# TMS320F280049 register map
Vendor: Texas Instruments; Series: C2000 F28004x; File version: 0.2.0-generated
Registers are 16-bit, read-write, reset 0x0 unless marked. A register's access mark holds for its fields unless they carry their own. Offsets are from the block's base; [hi:lo] are bit positions; {n}, {i} and the like mark numbered series.

## SYNCSOCREGS — SYNC SOC Registers
Base 0x0000F280
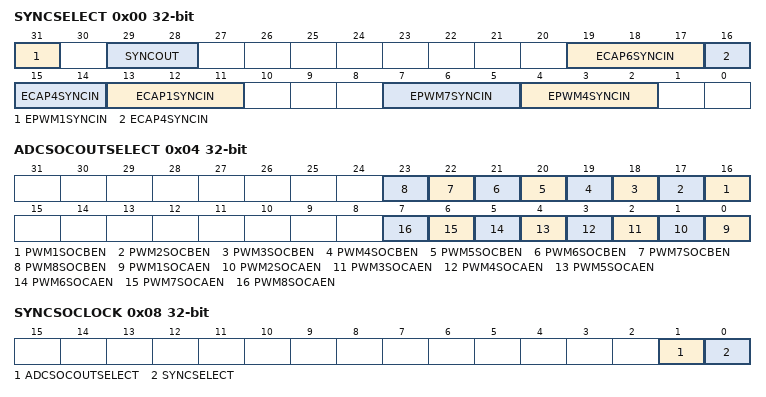
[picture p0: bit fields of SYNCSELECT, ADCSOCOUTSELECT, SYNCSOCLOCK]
0x00 SYNCSELECT 32-bit — Sync Input and Output Select Register
  [31] EPWM1SYNCIN — Selects Sync Input Source for EPWM1
  [29:28] SYNCOUT — Select Syncout Source
  [19:17] ECAP6SYNCIN — Selects Sync Input Source for ECAP6
  [16:14] ECAP4SYNCIN — Selects Sync Input Source for ECAP4
  [13:11] ECAP1SYNCIN — Selects Sync Input Source for ECAP1
  [7:5] EPWM7SYNCIN — Selects Sync Input Source for EPWM7
  [4:2] EPWM4SYNCIN — Selects Sync Input Source for EPWM4
0x04 ADCSOCOUTSELECT 32-bit — External ADCSOC Select Register
  [n+15] PWM{n}SOCBEN (n=1..8) — PWM{n}SOCBEN Enable for ADCSOCBOn
  [n-1] PWM{n}SOCAEN (n=1..8) — PWM{n}SOCAEN Enable for ADCSOCAOn
0x08 SYNCSOCLOCK 32-bit — SYNCSEL and EXTADCSOC Select Lock register
  [1] ADCSOCOUTSELECT — ADCSOCOUTSELECT Register Lock bit
  [0] SYNCSELECT — SYNCSEL Register Lock bit

## DMACLASRCSELREGS — DMA CLA SRC SEL Registers
Base 0x0000F300
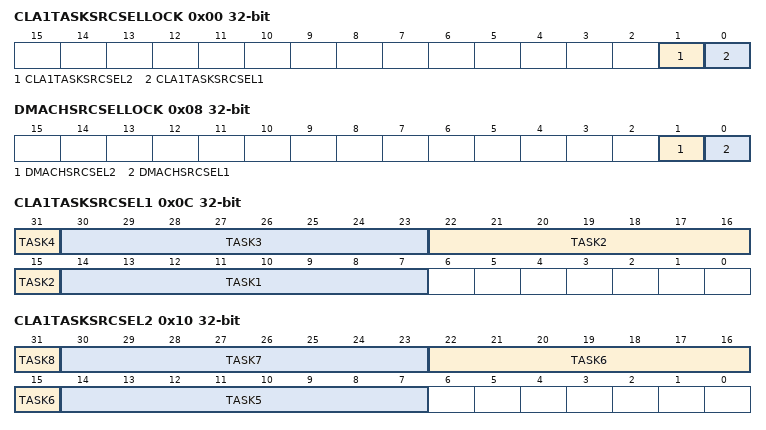
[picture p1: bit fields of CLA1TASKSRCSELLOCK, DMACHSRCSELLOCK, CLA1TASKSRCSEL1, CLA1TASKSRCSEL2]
0x00 CLA1TASKSRCSELLOCK 32-bit — CLA1 Task Trigger Source Select Lock Register
  [1] CLA1TASKSRCSEL2 — CLA1TASKSRCSEL2 Register Lock bit
  [0] CLA1TASKSRCSEL1 — CLA1TASKSRCSEL1 Register Lock bit
0x08 DMACHSRCSELLOCK 32-bit — DMA Channel Triger Source Select Lock Register
  [1] DMACHSRCSEL2 — DMACHSRCSEL2 Register Lock bit
  [0] DMACHSRCSEL1 — DMACHSRCSEL1 Register Lock bit
0x0C CLA1TASKSRCSEL1 32-bit — CLA1 Task Trigger Source Select Register-1
  [31] TASK4 — Selects the Trigger Source for TASK4 of CLA1
  [30:23] TASK3 — Selects the Trigger Source for TASK3 of CLA1
  [22:15] TASK2 — Selects the Trigger Source for TASK2 of CLA1
  [14:7] TASK1 — Selects the Trigger Source for TASK1 of CLA1
0x10 CLA1TASKSRCSEL2 32-bit — CLA1 Task Trigger Source Select Register-2
  [31] TASK8 — Selects the Trigger Source for TASK8 of CLA1
  [30:23] TASK7 — Selects the Trigger Source for TASK7 of CLA1
  [22:15] TASK6 — Selects the Trigger Source for TASK6 of CLA1
  [14:7] TASK5 — Selects the Trigger Source for TASK5 of CLA1
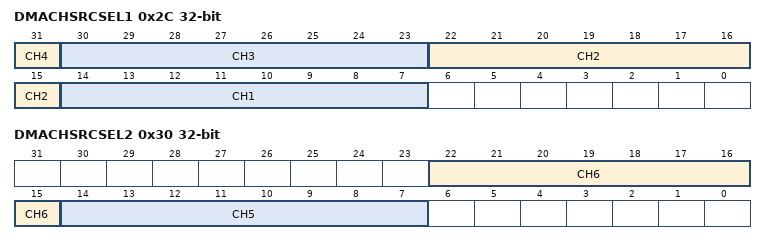
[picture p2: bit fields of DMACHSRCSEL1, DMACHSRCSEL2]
0x2C DMACHSRCSEL1 32-bit — DMA Channel Trigger Source Select Register-1
  [31] CH4 — Selects the Trigger and Sync Source CH4 of DMA
  [30:23] CH3 — Selects the Trigger and Sync Source CH3 of DMA
  [22:15] CH2 — Selects the Trigger and Sync Source CH2 of DMA
  [14:7] CH1 — Selects the Trigger and Sync Source CH1 of DMA
0x30 DMACHSRCSEL2 32-bit — DMA Channel Trigger Source Select Register-2
  [22:15] CH6 — Selects the Trigger and Sync Source CH6 of DMA
  [14:7] CH5 — Selects the Trigger and Sync Source CH5 of DMA

## GPIODATAREGS — GPIO DATA Registers
Base 0x0000FE00
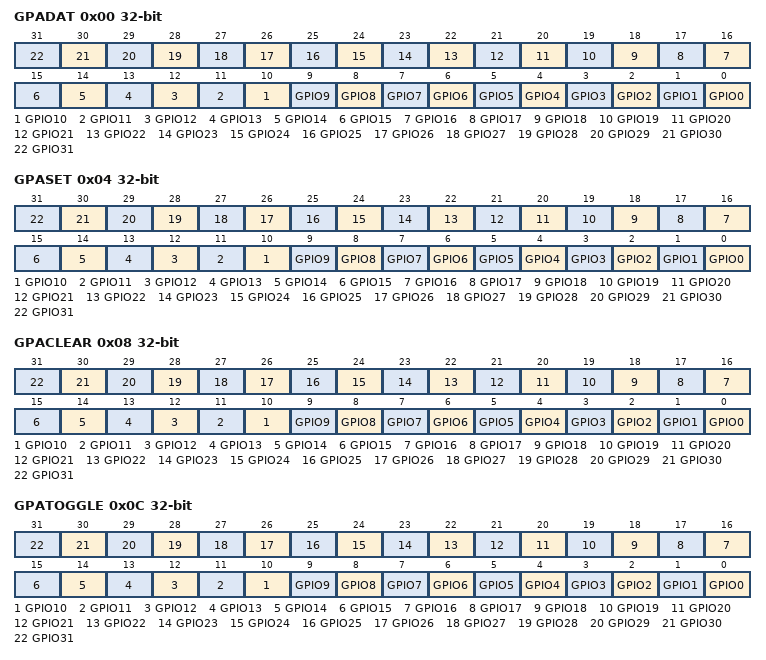
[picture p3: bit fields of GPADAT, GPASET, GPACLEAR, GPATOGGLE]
0x00 GPADAT 32-bit — GPIO A Data Register (GPIO0 to GPIO31)
  [n] GPIO{n} (n=0..31) — Data Register for this pin
0x04 GPASET 32-bit — GPIO A Output Set (GPIO0 to GPIO31)
  [n] GPIO{n} (n=0..31) — Output Set bit for this pin
0x08 GPACLEAR 32-bit — GPIO A Output Clear (GPIO0 to GPIO31)
  [n] GPIO{n} (n=0..31) — Output Clear bit for this pin
0x0C GPATOGGLE 32-bit — GPIO A Output Toggle (GPIO0 to GPIO31)
  [n] GPIO{n} (n=0..31) — Output Toggle bit for this pin
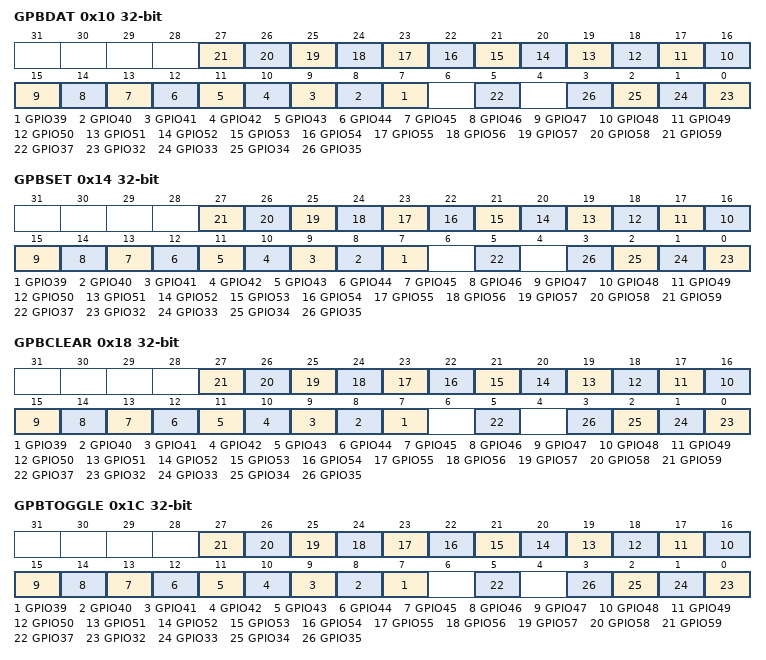
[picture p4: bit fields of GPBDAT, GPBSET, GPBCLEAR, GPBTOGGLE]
0x10 GPBDAT 32-bit — GPIO B Data Register (GPIO32 to GPIO64)
  [n-32] GPIO{n} (n=39..59) — Data Register for this pin
  [5] GPIO37 — Data Register for this pin
  [n-32] GPIO{n} (n=32..35) — Data Register for this pin
0x14 GPBSET 32-bit — GPIO B Output Set (GPIO32 to GPIO64)
  [n-32] GPIO{n} (n=39..59) — Output Set bit for this pin
  [5] GPIO37 — Output Set bit for this pin
  [n-32] GPIO{n} (n=32..35) — Output Set bit for this pin
0x18 GPBCLEAR 32-bit — GPIO B Output Clear (GPIO32 to GPIO64)
  [n-32] GPIO{n} (n=39..59) — Output Clear bit for this pin
  [5] GPIO37 — Output Clear bit for this pin
  [n-32] GPIO{n} (n=32..35) — Output Clear bit for this pin
0x1C GPBTOGGLE 32-bit — GPIO B Output Toggle (GPIO32 to GPIO64)
  [n-32] GPIO{n} (n=39..59) — Output Toggle bit for this pin
  [5] GPIO37 — Output Toggle bit for this pin
  [n-32] GPIO{n} (n=32..35) — Output Toggle bit for this pin
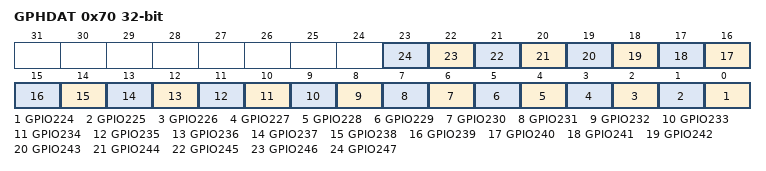
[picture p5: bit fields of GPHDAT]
0x70 GPHDAT 32-bit — GPIO H Data Register (GPIO0 to GPIO255)
  [n-224] GPIO{n} (n=224..247) — Data Register for this pin
